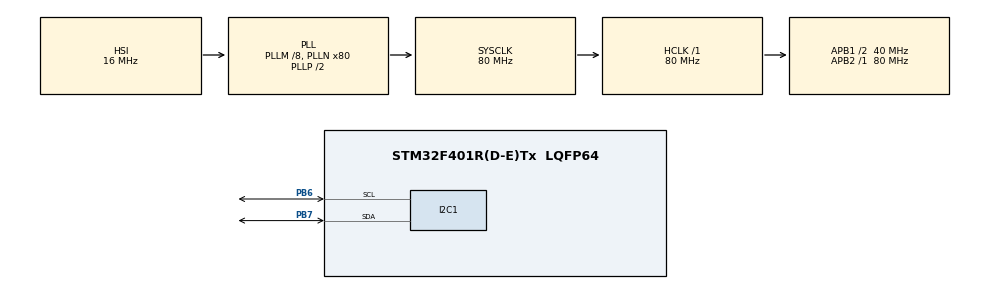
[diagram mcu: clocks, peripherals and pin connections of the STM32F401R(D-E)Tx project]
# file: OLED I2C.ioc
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Dma.I2C1_TX.0.Direction=DMA_MEMORY_TO_PERIPH
Dma.I2C1_TX.0.FIFOMode=DMA_FIFOMODE_DISABLE
Dma.I2C1_TX.0.Instance=DMA1_Stream6
Dma.I2C1_TX.0.MemDataAlignment=DMA_MDATAALIGN_BYTE
Dma.I2C1_TX.0.MemInc=DMA_MINC_ENABLE
Dma.I2C1_TX.0.Mode=DMA_NORMAL
Dma.I2C1_TX.0.PeriphDataAlignment=DMA_PDATAALIGN_BYTE
Dma.I2C1_TX.0.PeriphInc=DMA_PINC_DISABLE
Dma.I2C1_TX.0.Priority=DMA_PRIORITY_MEDIUM
Dma.Request0=I2C1_TX
I2C1.I2C_Mode=I2C_Fast
Mcu.Family=STM32F4
Mcu.Name=STM32F401R(D-E)Tx
Mcu.Package=LQFP64
NVIC.DMA1_Stream6_IRQn=true\:0\:0\:false\:false\:true\:false\:true
NVIC.I2C1_EV_IRQn=true\:10\:0\:true\:false\:true\:true\:true
NVIC.PriorityGroup=NVIC_PRIORITYGROUP_4
PA13.Mode=Serial_Wire
PA13.Signal=SYS_JTMS-SWDIO
PA14.Mode=Serial_Wire
PA14.Signal=SYS_JTCK-SWCLK
PB6.GPIO_Speed=GPIO_SPEED_FREQ_HIGH
PB6.Mode=I2C
PB6.Signal=I2C1_SCL
PB7.GPIO_Speed=GPIO_SPEED_FREQ_HIGH
PB7.Mode=I2C
PB7.Signal=I2C1_SDA
ProjectManager.HeapSize=0x200
ProjectManager.StackSize=0x400
ProjectManager.TargetToolchain=STM32CubeIDE
RCC.48MHZClocksFreq_Value=40000000
RCC.AHBFreq_Value=80000000
RCC.APB1CLKDivider=RCC_HCLK_DIV2
RCC.APB1Freq_Value=40000000
RCC.APB1TimFreq_Value=80000000
RCC.APB2Freq_Value=80000000
RCC.APB2TimFreq_Value=80000000
RCC.CortexFreq_Value=80000000
RCC.HCLKFreq_Value=80000000
RCC.HSE_VALUE=25000000
RCC.HSI_VALUE=16000000
RCC.LSE_VALUE=32768
RCC.PLLM=8
RCC.PLLN=80
RCC.SYSCLKFreq_VALUE=80000000
RCC.SYSCLKSource=RCC_SYSCLKSOURCE_PLLCLK
RCC.VCOOutputFreq_Value=160000000
board=custom

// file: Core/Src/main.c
/* USER CODE BEGIN Header */
/**
  ******************************************************************************
  * @file           : main.c
  * @brief          : Main program body
  ******************************************************************************
  * @attention
  *
  * Copyright (c) 2023 STMicroelectronics.
  * All rights reserved.
  *
  * This software is licensed under terms that can be found in the LICENSE file
  * in the root directory of this software component.
  * If no LICENSE file comes with this software, it is provided AS-IS.
  *
  ******************************************************************************
  */
/* USER CODE END Header */
#include "main.h"
#include "dma.h"
#include "i2c.h"
#include "gpio.h"

/* USER CODE BEGIN Includes */
#include "GFX.h"
/* USER CODE END Includes */

void SystemClock_Config(void);

int main(void)
{

  /* MCU Configuration--------------------------------------------------------*/

  /* Reset of all peripherals, Initializes the Flash interface and the Systick. */
  HAL_Init();

  /* Configure the system clock */
  SystemClock_Config();

  /* Initialize all configured peripherals */
  MX_GPIO_Init();
  MX_I2C1_Init();
  MX_DMA_Init();
  /* USER CODE BEGIN 2 */
SSD1306_init();
GFX_draw_fill_rect(4, 3, 4, 2, WHITE);
SSD1306_display_repaint();
  /* USER CODE END 2 */

  /* Infinite loop */
  while (1)
  {

  }
}

void SystemClock_Config(void)
{
  RCC_OscInitTypeDef RCC_OscInitStruct = {0};
  RCC_ClkInitTypeDef RCC_ClkInitStruct = {0};

  /** Configure the main internal regulator output voltage
  */
  __HAL_RCC_PWR_CLK_ENABLE();
  __HAL_PWR_VOLTAGESCALING_CONFIG(PWR_REGULATOR_VOLTAGE_SCALE2);
  /** Initializes the RCC Oscillators according to the specified parameters
  * in the RCC_OscInitTypeDef structure.
  */
  RCC_OscInitStruct.OscillatorType = RCC_OSCILLATORTYPE_HSI;
  RCC_OscInitStruct.HSIState = RCC_HSI_ON;
  RCC_OscInitStruct.HSICalibrationValue = RCC_HSICALIBRATION_DEFAULT;
  RCC_OscInitStruct.PLL.PLLState = RCC_PLL_ON;
  RCC_OscInitStruct.PLL.PLLSource = RCC_PLLSOURCE_HSI;
  RCC_OscInitStruct.PLL.PLLM = 8;
  RCC_OscInitStruct.PLL.PLLN = 80;
  RCC_OscInitStruct.PLL.PLLP = RCC_PLLP_DIV2;
  RCC_OscInitStruct.PLL.PLLQ = 4;
  if (HAL_RCC_OscConfig(&RCC_OscInitStruct) != HAL_OK)
  {
    Error_Handler();
  }
  /** Initializes the CPU, AHB and APB buses clocks
  */
  RCC_ClkInitStruct.ClockType = RCC_CLOCKTYPE_HCLK|RCC_CLOCKTYPE_SYSCLK
                              |RCC_CLOCKTYPE_PCLK1|RCC_CLOCKTYPE_PCLK2;
  RCC_ClkInitStruct.SYSCLKSource = RCC_SYSCLKSOURCE_PLLCLK;
  RCC_ClkInitStruct.AHBCLKDivider = RCC_SYSCLK_DIV1;
  RCC_ClkInitStruct.APB1CLKDivider = RCC_HCLK_DIV2;
  RCC_ClkInitStruct.APB2CLKDivider = RCC_HCLK_DIV1;

  if (HAL_RCC_ClockConfig(&RCC_ClkInitStruct, FLASH_LATENCY_2) != HAL_OK)
  {
    Error_Handler();
  }
}

void Error_Handler(void)
{
  __disable_irq();
  while (1)
  {
  }
}
